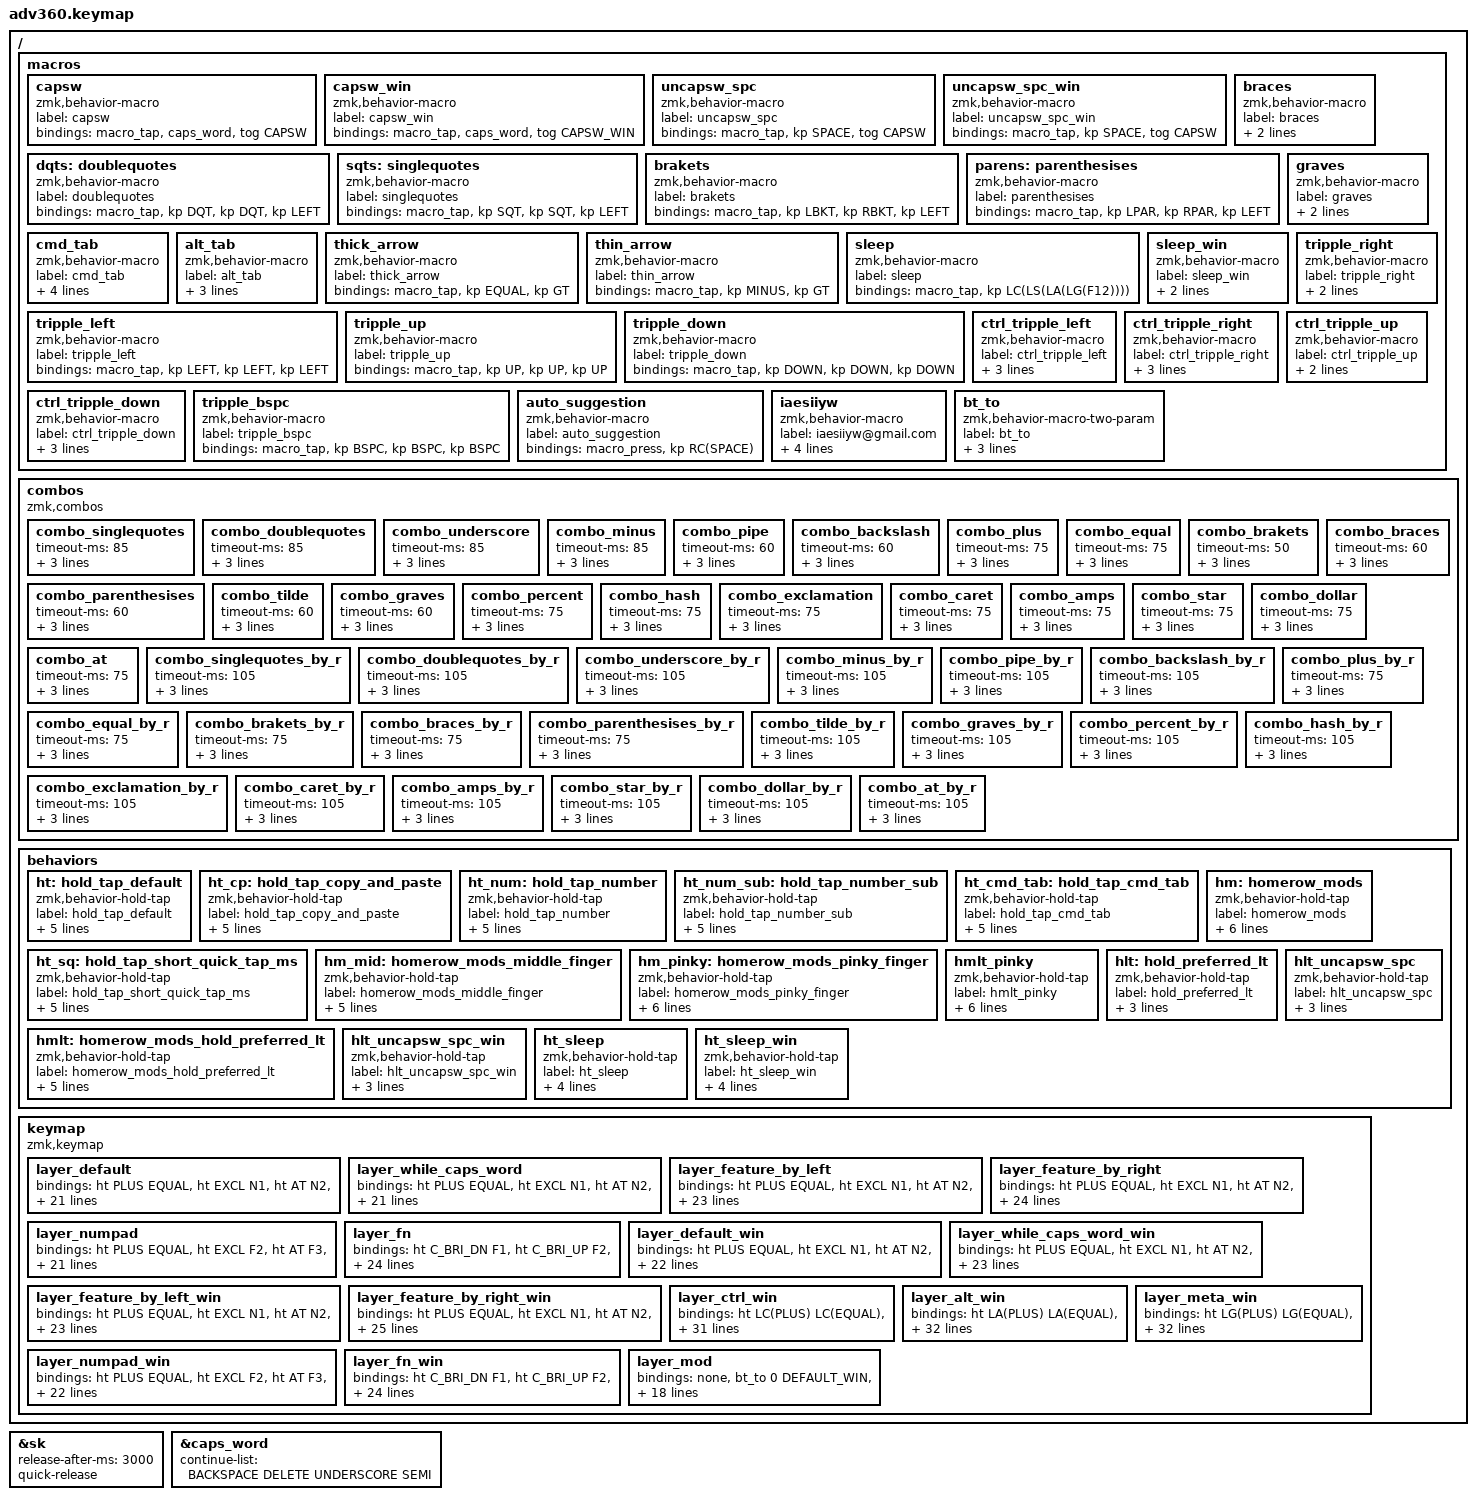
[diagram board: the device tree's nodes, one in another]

/*
 * Copyright (c) 2020 The ZMK Contributors
 *
 * SPDX-License-Identifier: MIT
 */


/* THIS FILE WAS GENERATED!
 *
 * This file was generated automatically. You may or may not want to
 * edit it directly.
 */

#include <behaviors.dtsi>
#include <dt-bindings/zmk/keys.h>
#include <dt-bindings/zmk/bt.h>
#include <dt-bindings/zmk/rgb.h>
#include <dt-bindings/zmk/backlight.h>

/* 
 * The order of layers matter.
 * When more than two layers are activated, 
 * higher one is to be actually used.
 * That's why, for example, ALT_WIN is higher than DEFAULT_WIN.
 * DEFAULT_WIN can trigger(&mo) ALT_WIN, so ALT_WIN's index must be higher.
 */
#define DEFAULT 0
#define CAPSW 1
#define FEAT_L 2
#define FEAT_R 3
#define NUM 4
#define FN 5
#define DEFAULT_WIN 6
#define CAPSW_WIN 7
#define FEAT_L_WIN 8
#define FEAT_R_WIN 9
#define CTRL_WIN 10
#define ALT_WIN 11
#define META_WIN 12
#define NUM_WIN 13
#define FN_WIN 14
#define MOD 15

&sk {
    release-after-ms = <3000>;
    quick-release;
};

&caps_word {
    continue-list = <BACKSPACE DELETE UNDERSCORE SEMI>;
};

/ {

    macros {
        capsw: capsw {
            label = "capsw";
            compatible = "zmk,behavior-macro";
            #binding-cells = <0>;
            bindings
                = <&macro_tap &caps_word &tog CAPSW>;
        };    
        capsw_win: capsw_win {
            label = "capsw_win";
            compatible = "zmk,behavior-macro";
            #binding-cells = <0>;
            bindings
                = <&macro_tap &caps_word &tog CAPSW_WIN>;
        };                       
        uncapsw_spc: uncapsw_spc {
            label = "uncapsw_spc";
            compatible = "zmk,behavior-macro";
            #binding-cells = <0>;
            bindings
                = <&macro_tap &kp SPACE &tog CAPSW>;
        };
        uncapsw_spc_win: uncapsw_spc_win {
            label = "uncapsw_spc_win";
            compatible = "zmk,behavior-macro";
            #binding-cells = <0>;
            bindings
                = <&macro_tap &kp SPACE &tog CAPSW>;
        };                          
        dqts: doublequotes {
            label = "doublequotes";
            compatible = "zmk,behavior-macro";
            #binding-cells = <0>;
            bindings
                = <&macro_tap &kp DQT &kp DQT &kp LEFT>;
        };
        sqts: singlequotes {
            label = "singlequotes";
            compatible = "zmk,behavior-macro";
            #binding-cells = <0>;
            bindings
                = <&macro_tap &kp SQT &kp SQT &kp LEFT>;
        };       
        brakets: brakets {
            label = "brakets";
            compatible = "zmk,behavior-macro";
            #binding-cells = <0>;
            bindings
                = <&macro_tap &kp LBKT &kp RBKT &kp LEFT>;
        };
        braces: braces {
            label = "braces";
            compatible = "zmk,behavior-macro";
            #binding-cells = <0>;
            bindings
                = <&macro_tap &kp LBRC &kp SPACE &kp SPACE &kp RBRC &kp LEFT &kp LEFT>;
        };
        parens: parenthesises {
            label = "parenthesises";
            compatible = "zmk,behavior-macro";
            #binding-cells = <0>;
            bindings
                = <&macro_tap &kp LPAR &kp RPAR &kp LEFT>;
        };
        graves: graves {
            label = "graves";
            compatible = "zmk,behavior-macro";
            #binding-cells = <0>;
            bindings
                = <&macro_tap &kp GRAVE &kp GRAVE &kp LEFT>;
        };
        cmd_tab: cmd_tab {
            label = "cmd_tab";
            compatible = "zmk,behavior-macro";
            #binding-cells = <0>;
            bindings
                = <&macro_press &kp LCMD>
                , <&macro_tap &kp TAB>
                , <&macro_pause_for_release>
                , <&macro_press &kp LEFT_ALT>
                , <&macro_release &kp LCMD &kp LEFT_ALT>;
        };
        alt_tab: alt_tab {
            label = "alt_tab";
            compatible = "zmk,behavior-macro";
            #binding-cells = <0>;
            bindings
                = <&macro_press &kp LALT>
                , <&macro_tap &kp TAB>
                , <&macro_pause_for_release>
                , <&macro_release &kp LALT>;
        };        
        thick_arrow: thick_arrow {
            label = "thick_arrow";
            compatible = "zmk,behavior-macro";
            #binding-cells = <0>;
            bindings
                = <&macro_tap &kp EQUAL &kp GT>;
        };
        thin_arrow: thin_arrow {
            label = "thin_arrow";
            compatible = "zmk,behavior-macro";
            #binding-cells = <0>;
            bindings
                = <&macro_tap &kp MINUS &kp GT>;
        };
        sleep: sleep {
            label = "sleep";
            compatible = "zmk,behavior-macro";
            #binding-cells = <0>;
            bindings
                = <&macro_tap &kp LC(LS(LA(LG(F12))))>;
        };
        sleep_win: sleep_win {
            label = "sleep_win";
            compatible = "zmk,behavior-macro";
            #binding-cells = <0>;
            bindings
                = <&macro_press &kp LMETA>
                /* I -> U, D -> S */                
                , <&macro_tap &kp X &kp I &kp D>
                , <&macro_release &kp LMETA>;
        };        
        tripple_left: tripple_left {
            label = "tripple_left";
            compatible = "zmk,behavior-macro";
            #binding-cells = <0>;
            bindings
                = <&macro_tap &kp LEFT &kp LEFT &kp LEFT>;
        };
        tripple_right: tripple_right {
            label = "tripple_right";
            compatible = "zmk,behavior-macro";
            #binding-cells = <0>;
            bindings
                = <&macro_tap &kp RIGHT &kp RIGHT &kp RIGHT>;
        };
        tripple_up: tripple_up {
            label = "tripple_up";
            compatible = "zmk,behavior-macro";
            #binding-cells = <0>;
            bindings
                = <&macro_tap &kp UP &kp UP &kp UP>;
        };
        tripple_down: tripple_down {
            label = "tripple_down";
            compatible = "zmk,behavior-macro";
            #binding-cells = <0>;
            bindings
                = <&macro_tap &kp DOWN &kp DOWN &kp DOWN>;
        };
        ctrl_tripple_left: ctrl_tripple_left {
            label = "ctrl_tripple_left";
            compatible = "zmk,behavior-macro";
            #binding-cells = <0>;
            bindings
                = <&macro_press &kp LCTRL>
                , <&macro_tap &kp LEFT &kp LEFT &kp LEFT>
                , <&macro_release &kp LCTRL>;                   
        };
        ctrl_tripple_right: ctrl_tripple_right {
            label = "ctrl_tripple_right";
            compatible = "zmk,behavior-macro";
            #binding-cells = <0>;
            bindings
                = <&macro_press &kp LCTRL>
                , <&macro_tap &kp RIGHT &kp RIGHT &kp RIGHT>
                , <&macro_release &kp LCTRL>;                
        };
        ctrl_tripple_up: ctrl_tripple_up {
            label = "ctrl_tripple_up";
            compatible = "zmk,behavior-macro";
            #binding-cells = <0>;
            bindings
                = <&macro_press &kp LCTRL>
                , <&macro_tap &kp UP &kp UP &kp UP>
                , <&macro_release &kp LCTRL>;                    
        };
        ctrl_tripple_down: ctrl_tripple_down {
            label = "ctrl_tripple_down";
            compatible = "zmk,behavior-macro";
            #binding-cells = <0>;
            bindings
                = <&macro_press &kp LCTRL>
                , <&macro_tap &kp DOWN &kp DOWN &kp DOWN>
                , <&macro_release &kp LCTRL>;                   
        };        
        tripple_bspc: tripple_bspc {
            label = "tripple_bspc";
            compatible = "zmk,behavior-macro";
            #binding-cells = <0>;
            bindings
                = <&macro_tap &kp BSPC &kp BSPC &kp BSPC>;
        };    
        auto_suggestion: auto_suggestion {
            label = "auto_suggestion";
            compatible = "zmk,behavior-macro";
            #binding-cells = <0>;
            bindings
            /* RC instead of LC, to avoid a collision, as RC is used lesser than LC. */   
                = <&macro_press &kp RC(SPACE)>;
        };                
        iaesiiyw: iaesiiyw {
            label = "iaesiiyw@gmail.com";
            compatible = "zmk,behavior-macro";
            #binding-cells = <0>;
            bindings
                = <&macro_tap &kp L &kp A &kp K &kp D &kp L &kp L &kp O &kp W &kp LS(N2) &kp T &kp M &kp A &kp L &kp U &kp DOT &kp C &kp SEMI &kp M>;
        };                               
        bt_to: bt_to {
            label = "bt_to";
            compatible = "zmk,behavior-macro-two-param";
            #binding-cells = <2>;
            bindings
                = <&macro_param_1to2>
                , <&bt BT_SEL MACRO_PLACEHOLDER>
                , <&macro_param_2to1>
                , <&to MACRO_PLACEHOLDER>;
        };        
    }; 

    combos {
        
        compatible = "zmk,combos";

        combo_singlequotes {
            timeout-ms = <85>;
            key-positions = <31 23>;
            bindings = <&sqts>;
            layers = <FEAT_L NUM FEAT_L_WIN NUM_WIN>;
        };
        combo_doublequotes {
            timeout-ms = <85>;
            key-positions = <32 23>;
            bindings = <&dqts>;
            layers = <FEAT_L NUM FEAT_L_WIN NUM_WIN>;
        };
        combo_underscore {
            timeout-ms = <85>;
            key-positions = <31 24>;
            bindings = <&kp UNDERSCORE>;
            layers = <FEAT_L NUM FEAT_L_WIN NUM_WIN>;
        };
        combo_minus {
            timeout-ms = <85>;
            key-positions = <32 24>;
            bindings = <&kp MINUS>;
            layers = <FEAT_L NUM FEAT_L_WIN NUM_WIN>;
        };
        combo_pipe {
            timeout-ms = <60>;
            key-positions = <31 25>;
            bindings = <&kp PIPE>;
            layers = <FEAT_L NUM FEAT_L_WIN NUM_WIN>;
        };
        combo_backslash {
            timeout-ms = <60>;
            key-positions = <32 25>;
            bindings = <&kp BSLH>;
            layers = <FEAT_L NUM FEAT_L_WIN NUM_WIN>;
        };
        combo_plus {
            timeout-ms = <75>;
            key-positions = <31 41>;
            bindings = <&kp PLUS>;
            layers = <FEAT_L NUM FEAT_L_WIN NUM_WIN>;
        };
        combo_equal {
            timeout-ms = <75>;
            key-positions = <32 41>;
            bindings = <&kp EQUAL>;
            layers = <FEAT_L NUM FEAT_L_WIN NUM_WIN>;
        };
        combo_brakets {
            timeout-ms = <50>;
            key-positions = <30 42>;
            bindings = <&brakets>;
            layers = <FEAT_L NUM FEAT_L_WIN NUM_WIN>;
        };
        combo_braces {
            timeout-ms = <60>;
            key-positions = <31 42>;
            bindings = <&braces>;
            layers = <FEAT_L NUM FEAT_L_WIN NUM_WIN>;
        };
        combo_parenthesises {
            timeout-ms = <60>;
            key-positions = <32 42>;
            bindings = <&parens>;
            layers = <FEAT_L NUM FEAT_L_WIN NUM_WIN>;
        };
        combo_tilde {
            timeout-ms = <60>;
            key-positions = <31 43>;
            bindings = <&kp TILDE>;
            layers = <FEAT_L NUM FEAT_L_WIN NUM_WIN>;
        };
        combo_graves {
            timeout-ms = <60>;
            key-positions = <32 43>;
            bindings = <&graves>;
            layers = <FEAT_L NUM FEAT_L_WIN NUM_WIN>;
        };
        combo_percent {
            timeout-ms = <75>;
            key-positions = <30 55>;
            bindings = <&kp PRCNT>;
            layers = <FEAT_L NUM FEAT_L_WIN NUM_WIN>;
        };
        combo_hash {
            timeout-ms = <75>;
            key-positions = <31 55>;
            bindings = <&kp HASH>;
            layers = <FEAT_L NUM FEAT_L_WIN NUM_WIN>;
        };
        combo_exclamation {
            timeout-ms = <75>;
            key-positions = <32 55>;
            bindings = <&kp EXCL>;
            layers = <FEAT_L NUM FEAT_L_WIN NUM_WIN>;
        };
        combo_caret {
            timeout-ms = <75>;
            key-positions = <30 56>;
            bindings = <&kp CARET>;
            layers = <FEAT_L NUM FEAT_L_WIN NUM_WIN>;
        };
        combo_amps {
            timeout-ms = <75>;
            key-positions = <31 56>;
            bindings = <&kp AMPS>;
            layers = <FEAT_L NUM FEAT_L_WIN NUM_WIN>;
        };
        combo_star {
            timeout-ms = <75>;
            key-positions = <32 56>;
            bindings = <&kp STAR>;
            layers = <FEAT_L NUM FEAT_L_WIN NUM_WIN>;
        };
        combo_dollar {
            timeout-ms = <75>;
            key-positions = <31 57>;
            bindings = <&kp DLLR>;
            layers = <FEAT_L NUM FEAT_L_WIN NUM_WIN>;
        };
        combo_at {
            timeout-ms = <75>;
            key-positions = <32 57>;
            bindings = <&kp AT>;
            layers = <FEAT_L NUM FEAT_L_WIN NUM_WIN>;
        };

        combo_singlequotes_by_r {
            timeout-ms = <105>;
            key-positions = <31 23>;
            bindings = <&sqts>;
            layers = <FEAT_R FEAT_R_WIN>;
        };
        combo_doublequotes_by_r {
            timeout-ms = <105>;
            key-positions = <32 23>;
            bindings = <&dqts>;
            layers = <FEAT_R FEAT_R_WIN>;
        };
        combo_underscore_by_r {
            timeout-ms = <105>;
            key-positions = <31 24>;
            bindings = <&kp UNDERSCORE>;
            layers = <FEAT_R FEAT_R_WIN>;
        };
        combo_minus_by_r {
            timeout-ms = <105>;
            key-positions = <32 24>;
            bindings = <&kp MINUS>;
            layers = <FEAT_R FEAT_R_WIN>;
        };
        combo_pipe_by_r {
            timeout-ms = <105>;
            key-positions = <31 25>;
            bindings = <&kp PIPE>;
            layers = <FEAT_R FEAT_R_WIN>;
        };
        combo_backslash_by_r {
            timeout-ms = <105>;
            key-positions = <32 25>;
            bindings = <&kp BSLH>;
            layers = <FEAT_R FEAT_R_WIN>;
        };
        combo_plus_by_r {
            timeout-ms = <75>;
            key-positions = <31 41>;
            bindings = <&kp PLUS>;
            layers = <FEAT_R FEAT_R_WIN>;
        };
        combo_equal_by_r {
            timeout-ms = <75>;
            key-positions = <32 41>;
            bindings = <&kp EQUAL>;
            layers = <FEAT_R FEAT_R_WIN>;
        };
        combo_brakets_by_r {
            timeout-ms = <75>;
            key-positions = <30 42>;
            bindings = <&brakets>;
            layers = <FEAT_R FEAT_R_WIN>;
        };
        combo_braces_by_r {
            timeout-ms = <75>;
            key-positions = <31 42>;
            bindings = <&braces>;
            layers = <FEAT_R FEAT_R_WIN>;
        };
        combo_parenthesises_by_r {
            timeout-ms = <75>;
            key-positions = <32 42>;
            bindings = <&parens>;
            layers = <FEAT_R FEAT_R_WIN>;
        };
        combo_tilde_by_r {
            timeout-ms = <105>;
            key-positions = <31 43>;
            bindings = <&kp TILDE>;
            layers = <FEAT_R FEAT_R_WIN>;
        };
        combo_graves_by_r {
            timeout-ms = <105>;
            key-positions = <32 43>;
            bindings = <&graves>;
            layers = <FEAT_R FEAT_R_WIN>;
        };
        combo_percent_by_r {
            timeout-ms = <105>;
            key-positions = <30 55>;
            bindings = <&kp PRCNT>;
            layers = <FEAT_R FEAT_R_WIN>;
        };
        combo_hash_by_r {
            timeout-ms = <105>;
            key-positions = <31 55>;
            bindings = <&kp HASH>;
            layers = <FEAT_R FEAT_R_WIN>;
        };
        combo_exclamation_by_r {
            timeout-ms = <105>;
            key-positions = <32 55>;
            bindings = <&kp EXCL>;
            layers = <FEAT_R FEAT_R_WIN>;
        };
        combo_caret_by_r {
            timeout-ms = <105>;
            key-positions = <30 56>;
            bindings = <&kp CARET>;
            layers = <FEAT_R FEAT_R_WIN>;
        };
        combo_amps_by_r {
            timeout-ms = <105>;
            key-positions = <31 56>;
            bindings = <&kp AMPS>;
            layers = <FEAT_R FEAT_R_WIN>;
        };
        combo_star_by_r {
            timeout-ms = <105>;
            key-positions = <32 56>;
            bindings = <&kp STAR>;
            layers = <FEAT_R FEAT_R_WIN>;
        };
        combo_dollar_by_r {
            timeout-ms = <105>;
            key-positions = <31 57>;
            bindings = <&kp DLLR>;
            layers = <FEAT_R FEAT_R_WIN>;
        };
        combo_at_by_r {
            timeout-ms = <105>;
            key-positions = <32 57>;
            bindings = <&kp AT>;
            layers = <FEAT_R FEAT_R_WIN>;
        };                   
    };

    behaviors {
        #include "macros.dtsi"
        #include "version.dtsi"

        ht: hold_tap_default {
            compatible = "zmk,behavior-hold-tap";
            label = "hold_tap_default";
            #binding-cells = <2>;
            tapping-term-ms = <175>;
            quick_tap_ms = <175>;
            global-quick-tap;
            flavor = "tap-preferred";
            bindings = <&kp>, <&kp>;
        };
        ht_cp: hold_tap_copy_and_paste {
            compatible = "zmk,behavior-hold-tap";
            label = "hold_tap_copy_and_paste";
            #binding-cells = <2>;
            tapping-term-ms = <140>;
            quick_tap_ms = <140>;
            global-quick-tap;
            flavor = "tap-preferred";
            bindings = <&kp>, <&kp>;
        };
        ht_num: hold_tap_number {
            compatible = "zmk,behavior-hold-tap";
            label = "hold_tap_number";
            #binding-cells = <2>;
            tapping-term-ms = <100>;
            quick_tap_ms = <100>;
            global-quick-tap;
            flavor = "tap-preferred";
            bindings = <&kp>, <&kp>;
        };
        ht_num_sub: hold_tap_number_sub {
            compatible = "zmk,behavior-hold-tap";
            label = "hold_tap_number_sub";
            #binding-cells = <2>;
            tapping-term-ms = <200>;
            quick_tap_ms = <100>;
            global-quick-tap;
            flavor = "tap-preferred";
            bindings = <&kp>, <&kp>;
        };
        ht_cmd_tab: hold_tap_cmd_tab {
            compatible = "zmk,behavior-hold-tap";
            label = "hold_tap_cmd_tab";
            #binding-cells = <2>;
            tapping-term-ms = <175>;
            quick_tap_ms = <175>;
            global-quick-tap;
            flavor = "tap-preferred";
            bindings = <&cmd_tab>, <&kp>;
        };
        ht_sq: hold_tap_short_quick_tap_ms {
            compatible = "zmk,behavior-hold-tap";
            label = "hold_tap_short_quick_tap_ms";
            #binding-cells = <2>;
            tapping-term-ms = <145>;
            quick_tap_ms = <100>; /* This short value is to prevent hold resolution when typing fast. */
            global-quick-tap;
            flavor = "tap-preferred";
            bindings = <&kp>, <&kp>;
        };
        hm: homerow_mods {
            compatible = "zmk,behavior-hold-tap";
            label = "homerow_mods";
            #binding-cells = <2>;
            tapping-term-ms = <175>;
            quick_tap_ms = <175>;
            global-quick-tap; 
            retro-tap;
            flavor = "balanced";
            bindings = <&kp>, <&kp>;
        };
        hm_mid: homerow_mods_middle_finger {
            compatible = "zmk,behavior-hold-tap";
            label = "homerow_mods_middle_finger";
            #binding-cells = <2>;
            tapping-term-ms = <150>; /* faster */
            quick_tap_ms = <150>;
            global-quick-tap;
            /* no retro-tap; */ /* Sometimes shift is used only with mouse, not other keys. */ 
            flavor = "balanced";
            bindings = <&kp>, <&kp>;
        };
        hm_pinky: homerow_mods_pinky_finger {
            compatible = "zmk,behavior-hold-tap";
            label = "homerow_mods_pinky_finger";
            #binding-cells = <2>;
            tapping-term-ms = <275>; /* slower as pinky has less muscular power */
            quick_tap_ms = <200>;
            global-quick-tap;
            retro-tap;
            flavor = "tap-preferred";
            bindings = <&kp>, <&kp>;
        };
        hmlt_pinky: hmlt_pinky {
            compatible = "zmk,behavior-hold-tap";
            label = "hmlt_pinky";
            #binding-cells = <2>;
            tapping-term-ms = <275>; /* slower as pinky has less muscular power */
            quick_tap_ms = <200>;
            global-quick-tap;
            retro-tap;
            flavor = "tap-preferred";
            bindings = <&mo>, <&kp>;
        };        
        hlt: hold_preferred_lt {
            compatible = "zmk,behavior-hold-tap";
            label = "hold_preferred_lt";
            #binding-cells = <2>;
            tapping-term-ms = <160>;
            flavor = "hold-preferred";
            bindings = <&mo>, <&kp>;
        };
        hmlt: homerow_mods_hold_preferred_lt {
            compatible = "zmk,behavior-hold-tap";
            label = "homerow_mods_hold_preferred_lt";
            #binding-cells = <2>;
            tapping-term-ms = <175>;
            quick_tap_ms = <175>;
            global-quick-tap;             
            flavor = "balanced";
            bindings = <&mo>, <&kp>;
        };        
        hlt_uncapsw_spc: hlt_uncapsw_spc {
            compatible = "zmk,behavior-hold-tap";
            label = "hlt_uncapsw_spc";
            #binding-cells = <2>;
            tapping-term-ms = <160>;
            flavor = "hold-preferred";
            bindings = <&mo>, <&uncapsw_spc>;     
        };  
        hlt_uncapsw_spc_win: hlt_uncapsw_spc_win {
            compatible = "zmk,behavior-hold-tap";
            label = "hlt_uncapsw_spc_win";
            #binding-cells = <2>;
            tapping-term-ms = <160>;
            flavor = "hold-preferred";
            bindings = <&mo>, <&uncapsw_spc_win>;     
        };                     
        ht_sleep: ht_sleep {
            compatible = "zmk,behavior-hold-tap";
            label = "ht_sleep";
            #binding-cells = <2>;
            tapping-term-ms = <175>;
            quick_tap_ms = <175>;
            flavor = "tap-preferred";
            bindings = <&sleep>, <&kp>;            
        };
        ht_sleep_win: ht_sleep_win {
            compatible = "zmk,behavior-hold-tap";
            label = "ht_sleep_win";
            #binding-cells = <2>;
            tapping-term-ms = <175>;
            quick_tap_ms = <175>;
            flavor = "tap-preferred";
            bindings = <&sleep_win>, <&kp>;            
        };        
    };

    keymap {
        compatible = "zmk,keymap";

        layer_default {
            bindings = <
                &ht PLUS EQUAL           &ht EXCL N1                 &ht AT N2                  &ht HASH N3                &ht DLLR N4                  &ht PRCNT N5            &to DEFAULT_WIN                                                                                                                             &mo MOD                   &ht CARET N6         &ht AMPS N7             &ht STAR N8                     &ht LPAR N9               &ht RPAR N0                 &ht UNDERSCORE MINUS
                &kp TAB                  &kp Q                       &kp W                      &kp E                      &kp R                        &kp T                   &to DEFAULT                   /* LG(P) */              /* LG(LS(P)) */                                              /* LG(T) */             &kp LG(Q)                 &kp Y                &kp U                   &kp I                           &kp O                     &ht_sq RS(P) P              &ht RS(BSLH) BSLH
                &kp CAPS                 &hm_pinky LCTRL A           &hm LALT S                 &hm_mid LSHFT D            &hm LCMD F                   &kp G                   &kp DEL                      &kp LG(R)                &kp LG(LS(R))                        &kp LCMD                &kp LG(F)                &ht_sleep 0 LG(W)         &kp H                &kp J                   &kp K                           &kp L                     &kp SEMI                    &ht RS(SQT) SQT
                &kp LSHFT                &kp Z                       &kp X                      &kp C                      &kp V                        &kp B                                                                         &kp HOME                             &iaesiiyw                                                                  &kp N                &kp M                   &ht RS(COMMA) COMMA             &ht RS(DOT) DOT           &ht RS(FSLH) FSLH           &kp RSHFT
                &mo FN                   &ht LS(GRAVE) GRAVE         &kp ENTER                  &kp LG(C)                  &kp LG(V)                                            &hlt FEAT_L BSPC             &hlt NUM RCMD            &kp LG(LS(E)) /* LG(LS(F)) */        &kp LG(E) /* LG(F) */   &hlt NUM ENTER           &hlt FEAT_R SPACE                              &kp TAB                 &none                           &ht RS(LBKT) LBKT         &ht RS(RBKT) RBKT           &mo FN
            >;          
        };          

        layer_while_caps_word {             
            bindings = <            
                &ht PLUS EQUAL           &ht EXCL N1                 &ht AT N2                  &ht HASH N3                &ht DLLR N4                  &ht PRCNT N5            &to DEFAULT_WIN                                                                                                                             &mo MOD                   &ht CARET N6         &ht AMPS N7             &ht STAR N8                     &ht LPAR N9               &ht RPAR N0                 &ht UNDERSCORE MINUS
                &kp TAB                  &kp Q                       &kp W                      &kp E                      &kp R                        &kp T                   &to DEFAULT                   /* LG(P) */              /* LG(LS(P)) */                                              /* LG(T) */             &kp LG(Q)                 &kp Y                &kp U                   &kp I                           &kp O                     &ht_sq RS(P) P              &ht RS(BSLH) BSLH
                &kp CAPS                 &hm_pinky LCTRL A           &hm LALT S                 &hm_mid LSHFT D            &hm LCMD F                   &kp G                   &kp DEL                      &kp LG(R)                &kp LG(LS(R))                        &kp LCMD                &kp LG(F)                &ht_sleep 0 LG(W)         &kp H                &kp J                   &kp K                           &kp L                     &kp RS(SEMI)                &ht RS(SQT) SQT
                &kp LSHFT                &kp Z                       &kp X                      &kp C                      &kp V                        &kp B                                                                         &kp HOME                             &iaesiiyw                                                                  &kp N                &kp M                   &ht RS(COMMA) COMMA             &ht RS(DOT) DOT           &ht RS(FSLH) FSLH           &kp RSHFT
                &mo FN                   &ht LS(GRAVE) GRAVE         &kp ENTER                  &kp LG(C)                  &kp LG(V)                                            &hlt FEAT_L BSPC             &hlt NUM RCMD            &kp LG(LS(F)) /* LG(LS(F)) */        &kp LG(F)               &hlt NUM ENTER           &hlt_uncapsw_spc FEAT_R 0                      &kp TAB                 &none                           &ht RS(LBKT) LBKT         &ht RS(RBKT) RBKT           &mo FN
            >;      
        };      

        layer_feature_by_left { /* Triggered by the left thumb */           
            bindings = <        
                &ht PLUS EQUAL           &ht EXCL N1                 &ht AT N2                  &ht HASH N3                &ht DLLR N4                  &ht PRCNT N5            &to DEFAULT_WIN                                                                                                                             &mo MOD                   &ht CARET N6         &ht AMPS N7             &tripple_up                     &ht LPAR N9               &ht RPAR N0                 &ht UNDERSCORE MINUS
                &kp TAB                  &kp Q                       &kp W                      &kp LG(A)                  &kp LG(GRAVE)                &kp LG(LS(V))           &to DEFAULT                                            /* LG(LS(P)) */                                                                      &kp LG(Q)                 &auto_suggestion     &thick_arrow            &kp UP                          &thin_arrow               &ht_sq RS(P) P              &ht RS(BSLH) BSLH
                &kp CAPS                 &kp LCTRL                   &kp LALT                   &kp LSHFT                  &kp LCMD                     &kp LG(Z)               &kp DEL                      &kp LCTRL                &kp LG(LS(R))                        &kp LCMD                &kp RCTRL                &ht_sleep 0 LG(W)         &tripple_left        &kp LEFT                &kp DOWN                        &kp RIGHT                 &tripple_right              &ht RS(SQT) SQT
                &kp LSHFT                &kp LG(Z)                   &kp LG(X)                  &ht_cp LG(V) LG(C)         &cmd_tab                     &kp LG(LS(Z))                                                                 &kp HOME                             &iaesiiyw                                                                  &ht RS(N) N          &capsw                  &tripple_down                   &thin_arrow               &ht RS(FSLH) FSLH           &kp RSHFT
                &mo FN                   &ht LS(GRAVE) GRAVE         &kp ENTER                  &kp LG(C)                  &kp LG(V)                                            &trans                       &hlt NUM RCMD            &kp END                              &kp PG_DN               &hlt NUM ENTER           &kp SPACE                                      &kp TAB                 &none                           &ht RS(LBKT) LBKT         &ht RS(RBKT) RBKT           &mo FN
            >;          
        };          

        layer_feature_by_right { /* Triggered by the right thumb */ /* DOT and COMMA are special hold_tap as they may be used for number-related tasks. */          
            bindings = <            
                &ht PLUS EQUAL           &ht EXCL N1                 &ht AT N2                  &ht HASH N3                &ht DLLR N4                  &ht PRCNT N5            &to DEFAULT_WIN                                                                                                                             &mo MOD                   &ht CARET N6         &ht AMPS N7             &ht STAR N8                     &ht LPAR N9               &ht RPAR N0                 &ht UNDERSCORE MINUS
                &kp TAB                  &kp Q                       &ht_num KP_N7 W            &ht_num KP_N8 E            &ht_num KP_N9 R              &kp T                   &to DEFAULT                                            /* LG(LS(P)) */                                                                      &kp LG(Q)                 &kp Y                &kp U                   &kp C_BRI_UP                    &ht RS(O) O               &ht_sq RS(P) P              &ht RS(BSLH) BSLH
                &kp CAPS                 &kp A                       &ht_num KP_N4 S            &ht_num KP_N5 D            &ht_num KP_N6 F              &kp G                   &kp DEL                      &kp LCTRL                &kp LG(LS(R))                        &kp LCMD                &kp RCTRL                &ht_sleep 0 LG(W)         &tripple_bspc        &hm LCMD BSPC           &hm_mid RSHFT ESC               &kp RALT                  &kp RCTRL                   &ht RS(SQT) SQT
                &kp LSHFT                &kp Z                       &ht_num KP_N1 X            &ht_num KP_N2 C            &ht_num KP_N3 V              &kp B                                                                         &kp HOME                             &iaesiiyw                                                                  &kp LG(S)            &sk RSHFT               &ht_num_sub RS(COMMA) COMMA     &kp DOT                   &ht RS(FSLH) FSLH           &kp RSHFT
                &mo FN                   &ht LS(GRAVE) GRAVE         &kp ENTER                  &ht_num KP_N0 CAPS         &kp LG(V)                                            &hlt FEAT_L BSPC             &hlt NUM RCMD            &kp END                              &kp PG_DN               &kp ENTER                &trans                                         &kp TAB                 &none                           &ht RS(LBKT) LBKT         &ht RS(RBKT) RBKT           &mo FN
            >;                  
        };                  

        layer_numpad { /* Triggered by the left and right thumbs */ /* DOT and COMMA are special hold_tap as they may be used for number-related tasks. */                  
            bindings = <                    
                &ht PLUS EQUAL           &ht EXCL F2                 &ht AT F3                  &ht HASH F4                &ht DLLR F5                  &ht PRCNT F6            &to DEFAULT_WIN                                                                                                                             &mo MOD                   &ht CARET F7         &ht AMPS F8             &ht STAR F9                     &ht LPAR F10              &ht RPAR F11                &ht UNDERSCORE MINUS
                &kp TAB                  &kp Q                       &kp KP_N7                  &kp KP_N8                  &kp KP_N9                    &kp T                   &to DEFAULT                                            /* LG(LS(P)) */                                                                      &kp LG(Q)                 &kp Y                &kp U                   &kp LS(LA(E)) /*vscode format*/ &ht RS(O) O               &ht_sq RS(P) P              &ht RS(BSLH) BSLH
                &kp CAPS                 &kp A                       &kp KP_N4                  &kp KP_N5                  &kp KP_N6                    &kp G                   &kp DEL                      &kp LCTRL                &kp LG(LS(R))                        &kp LCMD                &kp RCTRL                &ht_sleep 0 LG(W)         &kp C_VOL_UP         &kp C_BRI_UP            &auto_suggestion                &kp RALT                  &kp RCTRL                   &ht RS(SQT) SQT
                &kp LSHFT                &kp Z                       &kp KP_N1                  &kp KP_N2                  &kp KP_N3                    &kp B                                                                         &kp HOME                             &iaesiiyw                                                                  &kp C_VOL_DN         &kp C_BRI_DN            &kp LG(A)                       &kp DOT                   &ht RS(FSLH) FSLH           &kp RSHFT
                &mo FN                   &ht LS(GRAVE) GRAVE         &kp ENTER                  &kp KP_N0                  &kp LG(V)                                            &hlt FEAT_L BSPC             &kp RCMD                 &kp END                              &kp PG_DN               &kp ENTER                &hlt FEAT_R SPACE                              &kp TAB                 &none                           &ht RS(LBKT) LBKT         &ht RS(RBKT) RBKT           &mo FN
            >;                  
        };                  
        
        layer_fn {                  
            bindings = <                            
                &ht C_BRI_DN F1          &ht C_BRI_UP F2             &ht LC(UP) F3              &kp F4                     &ht C_REC F5                 &kp F6                  &to DEFAULT_WIN                                                                                                                             &mo MOD                   &ht C_PREV F7        &ht C_PP F8             &ht C_NEXT F9                   &ht C_MUTE F10            &ht C_VOL_DN F11            &ht C_VOL_UP F12
                &kp TAB                  &ht LS(Q) Q                 &ht LS(W) W                &ht LS(E) E                &ht LS(R) R                  &ht LS(T) T             &to DEFAULT                                            /* LG(LS(P)) */                                                                      &kp UP                    &ht RS(Y) Y          &ht RS(U) U             &ht RS(I) I                     &ht RS(O) O               &ht_sq RS(P) P              &ht RS(BSLH) BSLH
                &kp CAPS                 &hm_pinky LCTRL A           &hm LALT S                 &hm_mid LSHFT D            &hm LCMD F                   &ht LS(G) G             &ht N3 LG(R)                 &kp LCTRL                &kp LG(LS(R))                        &kp LCMD                &kp RCTRL                &ht_sleep 0 DOWN          &ht RS(H) H          &ht LCMD J              &hm_mid RSHFT K                 &hm RALT L                &hm_pinky RCTRL SEMI        &ht RS(SQT) SQT
                &kp LSHFT                &ht LG(Z) Z                 &ht LG(X) X                &ht LG(C) C                &ht LG(V) V                  &ht LS(B) B                                                                   &kp HOME                             &iaesiiyw                                                                  &ht RS(N) N          &ht RS(M) M             &ht_num_sub RS(COMMA) COMMA     &ht RS(DOT) DOT           &ht RS(FSLH) FSLH           &kp RSHFT
                &trans                   &ht LS(GRAVE) GRAVE         &kp ENTER                  &kp LG(C)                  &kp LG(V)                                            &kp BSPC                     &hlt NUM RCMD            &kp END                              &kp PG_DN               &kp ENTER                &kp SPACE                                      &kp TAB                 &none                           &ht RS(LBKT) LBKT         &ht RS(RBKT) RBKT           &trans
            >; 
        }; 
 
        layer_default_win { 
            bindings = < 
                &ht PLUS EQUAL           &ht EXCL N1                 &ht AT N2                  &ht HASH N3                &ht DLLR N4                  &ht PRCNT N5            &kp LA(LSHFT)                                                                                                                               &mo MOD                   &ht CARET N6         &ht AMPS N7             &ht STAR N8                     &ht LPAR N9               &ht RPAR N0                 &ht UNDERSCORE MINUS
                &kp TAB                  &kp Q                       &kp W                      &kp E                      &kp R                        &kp T                   &to LG(LS(SPACE))             /* LC(P) */              /* LC(LS(P)) */                                              /* LC(T) */             &kp LC(Q)                 &kp Y                &kp U                   &kp I                           &kp O                     &ht_sq RS(P) P              &ht RS(BSLH) BSLH
                &kp CAPS                 &hmlt_pinky META_WIN A      &hm LALT S                 &hm_mid LSHFT D            &hmlt CTRL_WIN F             &kp G                   &kp DEL                      &kp LC(R)                &kp LC(LS(R))                        &kp LCTRL               &kp LC(F)                &ht_sleep_win 0 LC(W)     &kp H                &kp J                   &kp K                           &kp L                     &kp SEMI                    &ht RS(SQT) SQT
                &kp LSHFT                &kp Z                       &kp X                      &kp C                      &kp V                        &kp B                                                                         &kp HOME                             &iaesiiyw                                                                  &kp N                &kp M                   &ht RS(COMMA) COMMA             &ht RS(DOT) DOT           &ht RS(FSLH) FSLH           &kp RSHFT
                &mo FN_WIN               &ht LS(GRAVE) GRAVE         &kp ENTER                  &kp LC(C)                  &kp LC(V)                                            &hlt FEAT_L_WIN BSPC         &hlt NUM_WIN RALT        &kp LC(LS(E)) /* LC(LS(F)) */        &kp LC(E) /* LC(F) */   &hlt NUM_WIN ENTER       &hlt FEAT_R_WIN SPACE                          &kp TAB                 &none                           &ht RS(LBKT) LBKT         &ht RS(RBKT) RBKT           &mo FN
            >; 
        };
 
        layer_while_caps_word_win {
            bindings = < 
                &ht PLUS EQUAL           &ht EXCL N1                 &ht AT N2                  &ht HASH N3                &ht DLLR N4                  &ht PRCNT N5            &to DEFAULT_WIN                                                                                                                             &mo MOD                   &ht CARET N6         &ht AMPS N7             &ht STAR N8                     &ht LPAR N9               &ht RPAR N0                 &ht UNDERSCORE MINUS
                &kp TAB                  &kp Q                       &kp W                      &kp E                      &kp R                        &kp T                   &to DEFAULT                   /* LC(P) */              /* LC(LS(P)) */                                              /* LC(T) */             &kp LC(Q)                 &kp Y                &kp U                   &kp I                           &kp O                     &ht_sq RS(P) P              &ht RS(BSLH) BSLH
                &kp CAPS                 &hmlt_pinky META_WIN A      &hm LALT S                 &hm_mid LSHFT D            &hmlt CTRL_WIN F             &kp G                   &kp DEL                      &kp LC(R)                &kp LC(LS(R))                        &kp LCTRL               &kp LC(F)                &ht_sleep_win 0 LC(W)     &kp H                &kp J                   &kp K                           &kp L                     &kp RS(SEMI)                &ht RS(SQT) SQT
                &kp LSHFT                &kp Z                       &kp X                      &kp C                      &kp V                        &kp B                                                                         &kp HOME                             &iaesiiyw                                                                  &kp N                &kp M                   &ht RS(COMMA) COMMA             &ht RS(DOT) DOT           &ht RS(FSLH) FSLH           &kp RSHFT
                &mo FN_WIN               &ht LS(GRAVE) GRAVE         &kp ENTER                  &kp LC(C)                  &kp LC(V)                                            &hlt FEAT_L_WIN BSPC         &hlt NUM_WIN RALT        &kp LC(LS(F)) /* LC(LS(F)) */        &kp LC(F)               &hlt NUM_WIN ENTER       &hlt_uncapsw_spc_win FEAT_R_WIN 0              &kp TAB                 &none                           &ht RS(LBKT) LBKT         &ht RS(RBKT) RBKT           &mo FN_WIN
            >;
        };

        layer_feature_by_left_win { /* Triggered by left thumb */  
            bindings = <
                &ht PLUS EQUAL           &ht EXCL N1                 &ht AT N2                  &ht HASH N3                &ht DLLR N4                  &ht PRCNT N5            &to DEFAULT_WIN                                                                                                                             &mo MOD                   &ht CARET N6         &ht AMPS N7             &tripple_up                     &ht LPAR N9               &ht RPAR N0                 &ht UNDERSCORE MINUS
                &kp TAB                  &kp Q                       &kp W                      &kp LC(A)                  &kp LC(GRAVE)                &kp LC(LS(V))           &to DEFAULT                                            /* LC(LS(P)) */                                                                      &kp LC(Q)                 &auto_suggestion     &thick_arrow            &kp UP                          &thin_arrow               &ht_sq RS(P) P              &ht RS(BSLH) BSLH
                &kp CAPS                 &kp LMETA                   &mo ALT_WIN                &kp LSHFT                  &mo CTRL_WIN                 &kp LC(Z)               &kp DEL                      &kp LMETA                &kp LC(LS(R))                        &kp LCTRL               &kp RMETA                &ht_sleep_win 0 LC(W)     &tripple_left        &kp LEFT                &kp DOWN                        &kp RIGHT                 &tripple_right              &ht RS(SQT) SQT
                &kp LSHFT                &kp LC(Z)                   &kp LC(X)                  &ht_cp LC(V) LC(C)         &alt_tab                     &kp LC(LS(Z))                                                                 &kp HOME                             &iaesiiyw                                                                  &ht RS(N) N          &capsw_win              &tripple_down                   &thin_arrow               &ht RS(FSLH) FSLH           &kp RSHFT
                &mo FN_WIN               &ht LS(GRAVE) GRAVE         &kp ENTER                  &kp LC(C)                  &kp LC(V)                                            &trans                       &hlt NUM_WIN RALT        &kp END                              &kp PG_DN               &hlt NUM_WIN ENTER       &kp SPACE                                      &kp TAB                 &none                           &ht RS(LBKT) LBKT         &ht RS(RBKT) RBKT           &mo FN_WIN
            >;  
        };         

        layer_feature_by_right_win { /* Triggered by right thumb */ /* DOT and COMMA are special hold_tap as they may be used for number-related tasks. */  
            bindings = <    
                &ht PLUS EQUAL           &ht EXCL N1                 &ht AT N2                  &ht HASH N3                &ht DLLR N4                  &ht PRCNT N5            &to DEFAULT_WIN                                                                                                                             &mo MOD                   &ht CARET N6         &ht AMPS N7             &ht STAR N8                     &ht LPAR N9               &ht RPAR N0                 &ht UNDERSCORE MINUS
                &kp TAB                  &kp Q                       &ht_num KP_N7 W            &ht_num KP_N8 E            &ht_num KP_N9 R              &kp T                   &to DEFAULT                                            /* LC(LS(P)) */                                                                      &kp LC(Q)                 &kp Y                &kp U                   &kp C_BRI_UP                    &ht RS(O) O               &ht_sq RS(P) P              &ht RS(BSLH) BSLH
                &kp CAPS                 &kp A                       &ht_num KP_N4 S            &ht_num KP_N5 D            &ht_num KP_N6 F              &kp G                   &kp DEL                      &kp LMETA                &kp LC(LS(R))                        &kp LCTRL               &kp RMETA                &ht_sleep_win 0 LC(W)     &tripple_bspc        &hm LCTRL BSPC          &hm_mid RSHFT ESC               &kp RALT                  &kp RMETA                   &ht RS(SQT) SQT
                &kp LSHFT                &kp Z                       &ht_num KP_N1 X            &ht_num KP_N2 C            &ht_num KP_N3 V              &kp B                                                                         &kp HOME                             &iaesiiyw                                                                  &kp LC(S)            &sk RSHFT               &ht_num_sub RS(COMMA) COMMA     &kp DOT                   &ht RS(FSLH) FSLH           &kp RSHFT
                &mo FN_WIN               &ht LS(GRAVE) GRAVE         &kp ENTER                  &ht_num KP_N0 CAPS         &kp LC(V)                                            &kp BSPC                     &hlt NUM_WIN RALT        &kp END                              &kp PG_DN               &kp ENTER                &trans                                         &kp TAB                 &none                           &ht RS(LBKT) LBKT         &ht RS(RBKT) RBKT           &mo FN_WIN
            >;                      
        };                

        layer_ctrl_win { /* Triggered by lctrl. LC(BSPC) -> DEL, LC(SPC) -> LG(S), LC(LEFT) -> HOME, LC(RIGHT) -> END, LC(UP) -> PG_UP, LC(DOWN) -> PG_DN  */  
            bindings = <
                &ht LC(PLUS) LC(EQUAL)   &ht LC(EXCL) LC(N1)         &ht LC(AT) LC(N2)          &ht LC(HASH) LC(N3)        &ht LC(DLLR) LC(N4)          &ht LC(PRCNT) LC(N5)    &to DEFAULT_WIN                                                                                                                             &mo MOD                   &ht LC(CARET) LC(N6) &ht LC(AMPS) LC(N7)     &ctrl_tripple_up                &ht LC(LPAR) LC(N9)       &ht LC(RPAR) LC(N0)         &ht LC(UNDERSCORE) LC(MINUS)
                &kp LC(TAB)              &kp LC(Q)                   &kp LC(W)                  &kp LC(A)                  &kp LC(GRAVE)                &kp LC(LS(V))           &to DEFAULT                                            /* LC(LS(P)) */                                                                      &kp LC(LC(Q))             &auto_suggestion     &thick_arrow            &kp PG_UP                       &thin_arrow               &ht_sq LC(RS(P)) LC(P)      &ht LC(RS(BSLH)) LC(BSLH)
                &kp LC(CAPS)             &hm_pinky LC(LMETA) LC(A)   &hm LC(LALT) LC(S)         &kp LSHFT                  &trans                       &kp LC(Z)               &kp LC(DEL)                  &kp LC(LMETA)            &kp LC(LS(R))                        &kp LCTRL               &kp LC(RMETA)            &ht_sleep_win 0 LC(LC(W)) &ctrl_tripple_left   &kp HOME                &kp PG_DN                       &kp END                   &ctrl_tripple_right         &ht LC(RS(SQT)) LC(SQT)
                &kp LC(LSHFT)            &kp LC(Z)                   &kp LC(X)                  &ht_cp LC(V) LC(C)         &alt_tab                     &kp LC(LS(Z))                                                                 &kp LC(HOME)                         &iaesiiyw                                         /* LG(S) */              &ht LC(RS(N)) LC(N)  &capsw_win              &ctrl_tripple_down              &thin_arrow               &ht LC(RS(FSLH)) LC(FSLH)   &kp LC(RSHFT)
                &mo FN_WIN               &ht LC(LS(GRAVE)) LC(GRAVE) &kp LC(ENTER)              &kp LC(C)                  &kp LC(V)                                            &kp DEL                      &hlt NUM_WIN LC(RALT)    &kp LC(END)                          &kp LC(PG_DN)           &hlt NUM_WIN LC(ENTER)   &kp LG(D)                                      &kp LC(TAB)             &none                           &ht LC(RS(LBKT)) LC(LBKT) &ht LC(RS(RBKT)) LC(RBKT)   &mo FN_WIN
            >;
        };

        layer_alt_win { /* Triggered by lalt. LA(LEFT, RIGHT) -> LG(LEFT, RIGHT) */  
            bindings = <
                &ht LA(PLUS) LA(EQUAL)   &ht LA(EXCL) LA(N1)         &ht LA(AT) LA(N2)          &ht LA(HASH) LA(N3)        &ht LA(DLLR) LA(N4)          &ht LA(PRCNT) LA(N5)    &to DEFAULT_WIN                                                                                                                             &mo MOD                   &ht LA(CARET) LA(N6) &ht LA(AMPS) LA(N7)     &ctrl_tripple_up                &ht LA(LPAR) LA(N9)       &ht LA(RPAR) LA(N0)         &ht LA(UNDERSCORE) LA(MINUS)
                &kp LA(TAB)              &kp LA(Q)                   &kp LA(W)                  &kp LA(LC(A))              &kp LA(LC(GRAVE))            &kp LA(LC(LS(V)))       &to DEFAULT                                            /* LC(LS(P)) */                                                                      &kp LA(LC(Q))             &auto_suggestion     &thick_arrow            &kp LA(UP)                      &thin_arrow               &ht_sq LA(RS(P)) LA(P)      &ht LA(RS(BSLH)) LA(BSLH)
                &kp LA(CAPS)             &kp LA(LMETA)               &trans                     &kp LSHFT                  &kp LA(LCTRL)                &kp LA(LC(Z))           &kp LA(DEL)                  &kp LA(LMETA)            &kp LC(LS(R))                        &kp LCTRL               &kp LA(RMETA)            &ht_sleep_win 0 LA(LC(W)) &ctrl_tripple_left   &kp LC(LEFT)            &kp LA(DOWN)                    &kp LC(RIGHT)             &ctrl_tripple_right         &ht LA(RS(SQT)) LA(SQT)
                &kp LA(LSHFT)            &kp LA(LC(Z))               &kp LA(LC(X))              &ht_cp LA(LC(V)) LA(LC(C)) &alt_tab                     &kp LA(LC(LS(Z)))                                                             &kp LA(HOME)                         &iaesiiyw                                                                  &ht LA(RS(N)) LA(N)  &capsw_win              &ctrl_tripple_down              &thin_arrow               &ht LA(RS(FSLH)) LA(FSLH)   &kp LA(RSHFT)
                &mo FN_WIN               &ht LA(LS(GRAVE)) LA(GRAVE) &kp LA(ENTER)              &kp LA(LC(C))              &kp LA(LC(V))                                        &trans                       &hlt NUM_WIN RALT        &kp LA(END)                          &kp LA(PG_DN)           &hlt NUM_WIN LA(ENTER)   &kp LA(SPACE)                                  &kp LA(TAB)             &none                           &ht LA(RS(LBKT)) LA(LBKT) &ht LA(RS(RBKT)) LA(RBKT)   &mo FN_WIN
            >;
        };   

        layer_meta_win { /* Triggered by lmeta. LG(C) -> LC(C) */  
            bindings = <
                &ht LG(PLUS) LG(EQUAL)   &ht LG(EXCL) LG(N1)         &ht LG(AT) LG(N2)          &ht LG(HASH) LG(N3)        &ht LG(DLLR) LG(N4)          &ht LG(PRCNT) LG(N5)    &to DEFAULT_WIN                                                                                                                             &mo MOD                   &ht LG(CARET) LG(N6) &ht LG(AMPS) LG(N7)     &ctrl_tripple_up                &ht LG(LPAR) LG(N9)       &ht LG(RPAR) LG(N0)         &ht LG(UNDERSCORE) LG(MINUS)
                &kp LG(TAB)              &kp LG(Q)                   &kp LG(W)                  &kp LG(LC(A))              &kp LG(LC(GRAVE))            &kp LG(LC(LS(V)))       &to DEFAULT                                            /* LC(LS(P)) */                                                                      &kp LG(LC(Q))             &auto_suggestion     &thick_arrow            &kp LC(UP)                      &thin_arrow               &ht_sq LG(RS(P)) LG(P)      &ht LG(RS(BSLH)) LG(BSLH)
                &kp LG(CAPS)             &trans                      &hm LG(LALT) LG(S)         &kp LG(LSHFT)              &kp LG(LCTRL)                &kp LG(LC(Z))           &kp LG(DEL)                  &kp LG(LMETA)            &kp LC(LS(R))                        &kp LCTRL               &kp LG(RMETA)            &ht_sleep_win 0 LG(LC(W)) &ctrl_tripple_left   &kp LC(LEFT)            &kp LC(DOWN)                    &kp LC(RIGHT)             &ctrl_tripple_right         &ht LG(RS(SQT)) LG(SQT)
                &kp LG(LSHFT)            &kp LG(LC(Z))               &kp LG(LC(X))              &kp LC(C)                  &alt_tab                     &kp LG(LC(LS(Z)))                                                             &kp LG(HOME)                         &iaesiiyw                                                                  &ht LG(RS(N)) LG(N)  &capsw_win              &ctrl_tripple_down              &thin_arrow               &ht LG(RS(FSLH)) LG(FSLH)   &kp LG(RSHFT)
                &mo FN_WIN               &ht LG(LS(GRAVE)) LG(GRAVE) &kp LG(ENTER)              &kp LG(LC(C))              &kp LG(LC(V))                                        &hlt FEAT_L_WIN BSPC         &hlt NUM_WIN RALT        &kp LG(END)                          &kp LG(PG_DN)           &hlt NUM_WIN LG(ENTER)   &kp LG(SPACE)                                  &kp LG(TAB)             &none                           &ht LG(RS(LBKT)) LG(LBKT) &ht LG(RS(RBKT)) LG(RBKT)   &mo FN_WIN
            >;
        };            
    
        layer_numpad_win { /* Triggered by left and right thumbs */ /* DOT and COMMA are special hold_tap as they may be used for number-related tasks. */                      
            bindings = <                        
                &ht PLUS EQUAL           &ht EXCL F2                 &ht AT F3                  &ht HASH F4                &ht DLLR F5                  &ht PRCNT F6            &to DEFAULT_WIN                                                                                                                             &mo MOD                   &ht CARET F7         &ht AMPS F8             &ht STAR F9                     &ht LPAR F10              &ht RPAR F11                &ht UNDERSCORE MINUS
                &kp TAB                  &kp Q                       &kp KP_N7                  &kp KP_N8                  &kp KP_N9                    &kp T                   &to DEFAULT                                            /* LC(LS(P)) */                                                                      &kp LC(Q)                 &kp Y                &kp U                   &kp LS(LA(E)) /*vscode format*/ &ht RS(O) O               &ht_sq RS(P) P              &ht RS(BSLH) BSLH
                &kp CAPS                 &kp A                       &kp KP_N4                  &kp KP_N5                  &kp KP_N6                    &kp G                   &kp DEL                      &kp LMETA                &kp LC(LS(R))                        &kp LCTRL               &kp RMETA                &ht_sleep_win 0 LC(W)     &kp C_VOL_UP         &kp C_BRI_UP            &auto_suggestion                &kp RALT                  &kp RMETA                   &ht RS(SQT) SQT
                &kp LSHFT                &kp Z                       &kp KP_N1                  &kp KP_N2                  &kp KP_N3                    &kp B                                                                         &kp HOME                             &iaesiiyw                                                                  &kp C_VOL_DN         &kp C_BRI_DN            &kp LC(A)                       &kp DOT                   &ht RS(FSLH) FSLH           &kp RSHFT
                &mo FN_WIN               &ht LS(GRAVE) GRAVE         &kp ENTER                  &kp KP_N0                  &kp LC(V)                                            &hlt FEAT_L_WIN BSPC         &kp RALT                 &kp END                              &kp PG_DN               &kp ENTER                &hlt FEAT_R_WIN SPACE                          &kp TAB                 &none                           &ht RS(LBKT) LBKT         &ht RS(RBKT) RBKT           &mo FN_WIN
            >;      
        };      
    
        layer_fn_win {      
            bindings = <            
                &ht C_BRI_DN F1          &ht C_BRI_UP F2             &ht LC(UP) F3              &kp F4                     &ht C_REC F5                 &kp F6                  &to DEFAULT_WIN                                                                                                                             &mo MOD                   &ht C_PREV F7        &ht C_PP F8             &ht C_NEXT F9                   &ht C_MUTE F10            &ht C_VOL_DN F11            &ht C_VOL_UP F12
                &kp TAB                  &ht LS(Q) Q                 &ht LS(W) W                &ht LS(E) E                &ht LS(R) R                  &ht LS(T) T             &to DEFAULT                                            /* LC(LS(P)) */                                                                      &kp UP                    &ht RS(Y) Y          &ht RS(U) U             &ht RS(I) I                     &ht RS(O) O               &ht_sq RS(P) P              &ht RS(BSLH) BSLH
                &kp CAPS                 &hm_pinky LMETA A           &hm LALT S                 &hm_mid LSHFT D            &hm LCTRL F                  &ht LS(G) G             &ht N3 LC(R)                 &kp LMETA                &kp LC(LS(R))                        &kp LCTRL               &kp RMETA                &ht_sleep_win 0 DOWN      &ht RS(H) H          &ht LCTRL J             &hm_mid RSHFT K                 &hm RALT L                &hm_pinky RMETA SEMI        &ht RS(SQT) SQT
                &kp LSHFT                &ht LC(Z) Z                 &ht LC(X) X                &ht LC(C) C                &ht LC(V) V                  &ht LS(B) B                                                                   &kp HOME                             &iaesiiyw                                                                  &ht RS(N) N          &ht RS(M) M             &ht_num_sub RS(COMMA) COMMA     &ht RS(DOT) DOT           &ht RS(FSLH) FSLH           &kp RSHFT
                &trans                   &ht LS(GRAVE) GRAVE         &kp ENTER                  &kp LC(C)                  &kp LC(V)                                            &kp BSPC                     &hlt NUM_WIN RALT        &kp END                              &kp PG_DN               &kp ENTER                &kp SPACE                                      &kp TAB                 &none                           &ht RS(LBKT) LBKT         &ht RS(RBKT) RBKT           &trans
            >;      
        };              
        
        layer_mod {     
            bindings = <                
                &none                    &bt_to 0 DEFAULT_WIN        &bt_to 1 DEFAULT_WIN       &bt_to 2 DEFAULT           &bt_to 3 DEFAULT             &bt_to 4 DEFAULT        &none                                                                                                                                       &trans                    &bt_to 5 DEFAULT_WIN &bt_to 6 DEFAULT_WIN    &bt_to 7 DEFAULT                &bt_to 8 DEFAULT          &bt_to 9 DEFAULT            &none
                &none                    &none                       &none                      &none                      &none                        &none                   &bootloader                                                                                                                                 &bootloader               &none                &none                   &none                           &none                     &none                       &none
                &none                    &none                       &none                      &none                      &none                        &none                   &rgb_ug RGB_MEFS_CMD 5       &bt BT_CLR               &bt BT_CLR_ALL                       &bt BT_CLR_ALL          &bt BT_CLR               &rgb_ug RGB_MEFS_CMD 5    &none                &none                   &none                           &none                     &none                       &none
                &none                    &none                       &none                      &none                      &none                        &none                                                                         &none                                &none                                                                      &none                &none                   &none                           &none                     &none                       &none
                &none                    &none                       &none                      &bl BL_INC                 &bl BL_DEC                                           &rgb_ug RGB_TOG              &bl BL_TOG               &none                                &none                   &bl BL_TOG               &rgb_ug RGB_TOG                                &bl BL_INC              &bl BL_DEC                      &none                     &none                       &none
            >;
        };
    };
};
